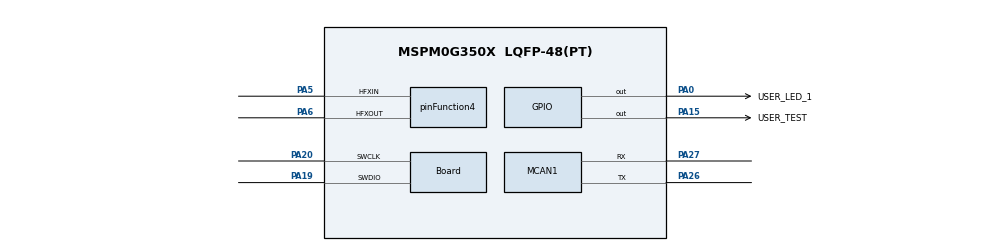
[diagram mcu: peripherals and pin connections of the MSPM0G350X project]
/**
 * @cliArgs --device "MSPM0G350X" --package "LQFP-48(PT)" --part "Default" --product "mspm0_sdk@1.30.00.03"
 * @versions {"tool":"1.19.0+3426"}
 */

/**
 * Import the modules used in this configuration.
 */
const GPIO          = scripting.addModule("/ti/driverlib/GPIO", {}, false);
const GPIO1         = GPIO.addInstance();
const MCAN          = scripting.addModule("/ti/driverlib/MCAN", {}, false);
const MCAN1         = MCAN.addInstance();
const SYSCTL        = scripting.addModule("/ti/driverlib/SYSCTL");
const ProjectConfig = scripting.addModule("/ti/project_config/ProjectConfig");

/**
 * Write custom configuration values to the imported modules.
 */
const divider7       = system.clockTree["PLL_PDIV"];
divider7.divideValue = 2;

const multiplier2         = system.clockTree["PLL_QDIV"];
multiplier2.multiplyValue = 5;

const mux4       = system.clockTree["EXHFMUX"];
mux4.inputSelect = "EXHFMUX_XTAL";

const mux8       = system.clockTree["HSCLKMUX"];
mux8.inputSelect = "HSCLKMUX_SYSPLL0";

const pinFunction3     = system.clockTree["HFCLKEXT"];
pinFunction3.inputFreq = 40;

const pinFunction4                        = system.clockTree["HFXT"];
pinFunction4.HFXTStartup                  = 10;
pinFunction4.HFCLKMonitor                 = true;
pinFunction4.enable                       = true;
pinFunction4.inputFreq                    = 12;
pinFunction4.peripheral.$assign           = "SYSCTL";
pinFunction4.peripheral.hfxInPin.$assign  = "PA5";
pinFunction4.peripheral.hfxOutPin.$assign = "PA6";

const namedConnection18 = system.clockTree["net_vco"];
scripting.suppress("MSPM0G currently only includes internal parameters to support configuring fVCO at a 				recommended frequency of 160MHz\\. Pending characterization, other frequencies might result in reduced 				accuracy or the PLL locking onto a wrong frequency entirely\\.", namedConnection18);

GPIO1.$name                                 = "GPIO_LEDS";
GPIO1.associatedPins.create(2);
GPIO1.associatedPins[0].$name               = "USER_LED_1";
GPIO1.associatedPins[0].assignedPort        = "PORTA";
GPIO1.associatedPins[0].assignedPortSegment = "Lower";
GPIO1.associatedPins[0].assignedPin         = "0";
GPIO1.associatedPins[0].invert              = "ENABLE";
GPIO1.associatedPins[0].pin.$assign         = "PA0";
GPIO1.associatedPins[1].$name               = "USER_TEST";
GPIO1.associatedPins[1].assignedPort        = "PORTA";
GPIO1.associatedPins[1].assignedPortSegment = "Lower";
GPIO1.associatedPins[1].assignedPin         = "15";
GPIO1.associatedPins[1].invert              = "ENABLE";
GPIO1.associatedPins[1].pin.$assign         = "PA15";

const Board                       = scripting.addModule("/ti/driverlib/Board", {}, false);
Board.peripheral.$assign          = "DEBUGSS";
Board.peripheral.swclkPin.$assign = "PA20";
Board.peripheral.swdioPin.$assign = "PA19";

MCAN1.$name                     = "MCAN0";
MCAN1.wkupReqEnable             = true;
MCAN1.autoWkupEnable            = true;
MCAN1.emulationEnable           = true;
MCAN1.tdcEnable                 = true;
MCAN1.rrfe                      = true;
MCAN1.rrfs                      = true;
MCAN1.anfe                      = "1";
MCAN1.anfs                      = "1";
MCAN1.stdFiltElem               = "111";
MCAN1.stdFiltType               = "00";
MCAN1.stdFiltID1                = 4;
MCAN1.enableInterrupt           = true;
MCAN1.interruptLine             = ["DL_MCAN_INTR_LINE_NUM_1"];
MCAN1.interruptLine1Flag        = ["DL_MCAN_INTR_MASK_ALL"];
MCAN1.m0interrupts              = ["DL_MCAN_MSP_INTERRUPT_LINE1"];
MCAN1.fdMode                    = false;
MCAN1.interruptFlags            = ["DL_MCAN_INTERRUPT_DRX","DL_MCAN_INTERRUPT_RF0N","DL_MCAN_INTERRUPT_TC"];
MCAN1.desiredNomRate            = 1000;
MCAN1.dataTimeSeg1_manual       = 7;
MCAN1.dataTimeSeg2_manual       = 2;
MCAN1.dataSynchJumpWidth_manual = 3;
MCAN1.loopbackMode              = "external";
MCAN1.peripheral.$assign        = "CANFD0";
MCAN1.peripheral.rxPin.$assign  = "PA27";
MCAN1.peripheral.txPin.$assign  = "PA26";
MCAN1.txPinConfig.$name         = "ti_driverlib_gpio_GPIOPinGeneric0";
MCAN1.rxPinConfig.$name         = "ti_driverlib_gpio_GPIOPinGeneric1";
scripting.suppress("MCAN is intended to work at the frequencies of 20, 40 or 80 Mhz\\.", MCAN1, "mcan_freq");

SYSCTL.CANCLKSource          = "HFCLK";
SYSCTL.useHFCLK_Manual       = true;
SYSCTL.HFCLKSource           = "HFXT";
SYSCTL.HFCLK_Freq            = 48000000;
SYSCTL.HFCLKMonitor          = true;
SYSCTL.HFXTStartup           = 10;
SYSCTL.forceDefaultClkConfig = true;
SYSCTL.clockTreeEn           = true;

ProjectConfig.deviceSpin = "MSPM0G3507";
scripting.suppress("Migrating requires going through the Switch Board or Device menu in the Device View section\\.", ProjectConfig, "deviceSpin");
